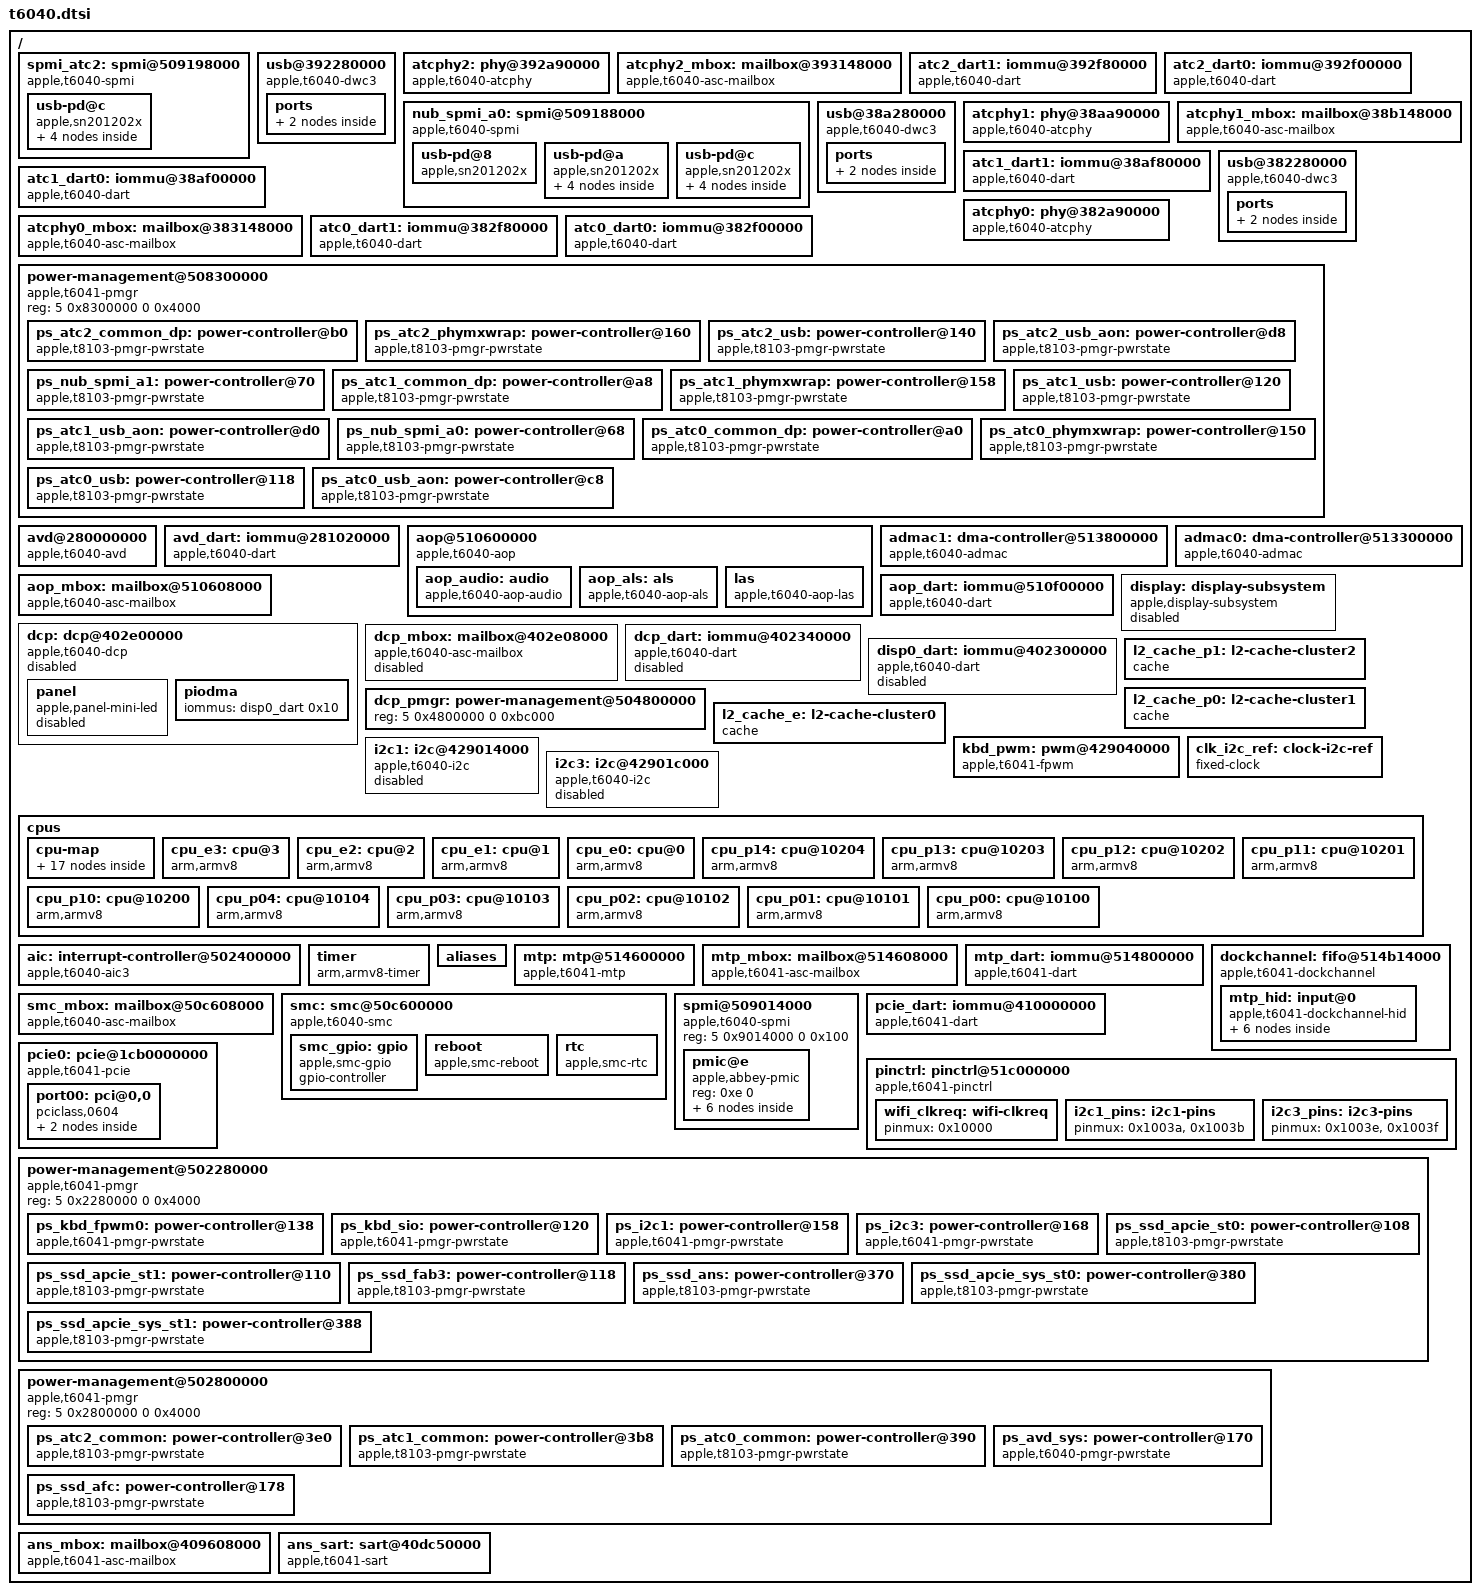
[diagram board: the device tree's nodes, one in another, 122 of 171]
// SPDX-License-Identifier: GPL-2.0+ OR MIT
/*
 * Apple T6040 (M4 Pro) SoC. Unit addresses are the ADT /arm-io addresses plus the 0x2_00000000 arm-io base.
 */

/ {
	#address-cells = <2>;
	#size-cells = <2>;

	/*
	 * The right-hand USB-C port (ATC2): the PD controller on its own SPMI bus, the ATC2 power states, both DARTs,
	 * the USB2 PHY and the dwc3 (USB2 host with hotplug). The two left ports below are the same stack.
	 */
	spmi_atc2: spmi@509198000 {
		compatible = "apple,t6040-spmi", "apple,spmi";
		reg = <5 0x9198000 0 0x100>;
		#address-cells = <2>;
		#size-cells = <0>;
		interrupt-controller;
		#interrupt-cells = <2>;
		interrupt-parent = <&aic>;
		interrupts = <0 0x364 4>;
		power-domains = <&ps_nub_spmi_a1>;

		usb-pd@c {
			compatible = "apple,sn201202x";
			reg = <0xc 0>;
			interrupts = <0xb 1 0xd 1 0x11 1 0x13 1>;
			interrupt-names = "irq", "select", "sleep", "wake";

			connector {
				compatible = "usb-c-connector";
				label = "USB-C Right";
				power-role = "dual";
				data-role = "dual";

				/*
				 * The HS endpoint names the dwc3 role switch: tipd looks it up at probe and defers
				 * until dwc3-apple has registered it.
				 */
				ports {
					#address-cells = <1>;
					#size-cells = <0>;

					port@0 {
						reg = <0>;
						typec2_connector_hs: endpoint {
							remote-endpoint = <&dwc3_2_hs>;
						};
					};
				};
			};
		};
	};

	usb@392280000 {
		compatible = "apple,t6040-dwc3", "apple,t8103-dwc3";
		reg = <3 0x92280000 0 0xcd00 3 0x9228cd00 0 0x3200>;
		reg-names = "dwc3-core", "dwc3-apple";
		interrupt-parent = <&aic>;
		interrupts = <0 0x693 4>;
		/*
		 * Role switch, not a fixed host: the PD controller resets the eUSB2 repeater on every CC connect, so the
		 * USB2 PHY and the core must start after the attach and stop on detach. The PHY has no device mode.
		 */
		dr_mode = "otg";
		usb-role-switch;
		role-switch-default-mode = "host";
		iommus = <&atc2_dart0 0 &atc2_dart1 1>;
		power-domains = <&ps_atc2_usb>;
		resets = <&atcphy2>;
		phys = <&atcphy2 3>;
		phy-names = "usb2-phy";

		ports {
			#address-cells = <1>;
			#size-cells = <0>;

			port@0 {
				reg = <0>;
				dwc3_2_hs: endpoint {
					remote-endpoint = <&typec2_connector_hs>;
				};
			};
		};
	};

	atcphy2: phy@392a90000 {
		compatible = "apple,t6040-atcphy";
		reg = <3 0x92a90000 0 0x4000 3 0x92800000 0 0x4000 3 0x92a84000 0 0x4000>;
		reg-names = "bank0", "bank1", "pipehandler";
		#phy-cells = <1>;
		#reset-cells = <0>;
		power-domains = <&ps_atc2_common_dp>;
		mboxes = <&atcphy2_mbox>;
		mbox-names = "phy-cpu";
	};

	/*
	 * The PHY coprocessor (ADT acio-phy-cpuN, "iop,mxwrap", RTKit) runs the SuperSpeed
	 * bring-up; its ASC v4 mailbox. ADT lists the IRQs as 1, 0, 3, 2 of the block,
	 * as for AOP: send-empty is the lowest.
	 */
	atcphy2_mbox: mailbox@393148000 {
		compatible = "apple,t6040-asc-mailbox", "apple,asc-mailbox-v4";
		reg = <3 0x93148000 0 0x4000>;
		interrupt-parent = <&aic>;
		interrupts = <0 0x3be 4 0 0x3bf 4 0 0x3c0 4 0 0x3c1 4>;
		interrupt-names = "send-empty", "send-not-empty", "recv-empty", "recv-not-empty";
		#mbox-cells = <0>;
		power-domains = <&ps_atc2_phymxwrap>;
	};

	atc2_dart1: iommu@392f80000 {
		compatible = "apple,t6040-dart", "apple,t8110-dart";
		reg = <3 0x92f80000 0 0x4000>;
		interrupt-parent = <&aic>;
		interrupts = <0 0x697 4>;
		power-domains = <&ps_atc2_usb>;
		#iommu-cells = <1>;
	};

	atc2_dart0: iommu@392f00000 {
		compatible = "apple,t6040-dart", "apple,t8110-dart";
		reg = <3 0x92f00000 0 0x4000>;
		interrupt-parent = <&aic>;
		interrupts = <0 0x697 4>;
		power-domains = <&ps_atc2_usb>;
		#iommu-cells = <1>;
	};

	/*
	 * The two left USB-C ports: left-front ATC1 (PD controller hpm1, SID 0xa) and left-back ATC0 (hpm0, SID 0xc),
	 * both PD controllers on nub-spmi-a0. Every ATCn address is ATC2's minus (2 - n) * 0x8000000 and every IRQ
	 * ATC2's minus (2 - n) * 0x20. The ADT lists only irq/sleep/wake; select is irq + 2, as on hpm2.
	 * nub-spmi-a0 also carries hpm5, the MagSafe 3 port (SID 8).
	 */
	nub_spmi_a0: spmi@509188000 {
		compatible = "apple,t6040-spmi", "apple,spmi";
		reg = <5 0x9188000 0 0x100>;
		#address-cells = <2>;
		#size-cells = <0>;
		interrupt-controller;
		#interrupt-cells = <2>;
		interrupt-parent = <&aic>;
		interrupts = <0 0x362 4>;
		power-domains = <&ps_nub_spmi_a0>;

		/*
		 * hpm5, the MagSafe 3 port's PD controller (ADT port-type 0x11, "Power In",
		 * no USB data path, no connector). tipd takes the port's capabilities from
		 * the controller and registers a Type-C port and a power supply for it, as
		 * for MagSafe on the M1 Pro/Max and the M2 Airs. Select is irq + 2.
		 */
		usb-pd@8 {
			compatible = "apple,sn201202x";
			reg = <0x8 0>;
			interrupts = <0x3f 1 0x41 1 0x45 1 0x47 1>;
			interrupt-names = "irq", "select", "sleep", "wake";
		};

		usb-pd@a {
			compatible = "apple,sn201202x";
			reg = <0xa 0>;
			interrupts = <0x25 1 0x27 1 0x2b 1 0x2d 1>;
			interrupt-names = "irq", "select", "sleep", "wake";

			connector {
				compatible = "usb-c-connector";
				label = "USB-C Left Front";
				power-role = "dual";
				data-role = "dual";

				ports {
					#address-cells = <1>;
					#size-cells = <0>;

					port@0 {
						reg = <0>;
						typec1_connector_hs: endpoint {
							remote-endpoint = <&dwc3_1_hs>;
						};
					};
				};
			};
		};

		/*
		 * hpm0, the left-back port's PD controller. DFU belongs to the boot ROM,
		 * before any OS runs, and macOS uses this port as a plain USB port too.
		 */
		usb-pd@c {
			compatible = "apple,sn201202x";
			reg = <0xc 0>;
			interrupts = <0xb 1 0xd 1 0x11 1 0x13 1>;
			interrupt-names = "irq", "select", "sleep", "wake";

			connector {
				compatible = "usb-c-connector";
				label = "USB-C Left Back";
				power-role = "dual";
				data-role = "dual";

				ports {
					#address-cells = <1>;
					#size-cells = <0>;

					port@0 {
						reg = <0>;
						typec0_connector_hs: endpoint {
							remote-endpoint = <&dwc3_0_hs>;
						};
					};
				};
			};
		};
	};

	usb@38a280000 {
		compatible = "apple,t6040-dwc3", "apple,t8103-dwc3";
		reg = <3 0x8a280000 0 0xcd00 3 0x8a28cd00 0 0x3200>;
		reg-names = "dwc3-core", "dwc3-apple";
		interrupt-parent = <&aic>;
		interrupts = <0 0x673 4>;
		dr_mode = "otg";
		usb-role-switch;
		role-switch-default-mode = "host";
		iommus = <&atc1_dart0 0 &atc1_dart1 1>;
		power-domains = <&ps_atc1_usb>;
		resets = <&atcphy1>;
		phys = <&atcphy1 3>;
		phy-names = "usb2-phy";

		ports {
			#address-cells = <1>;
			#size-cells = <0>;

			port@0 {
				reg = <0>;
				dwc3_1_hs: endpoint {
					remote-endpoint = <&typec1_connector_hs>;
				};
			};
		};
	};

	atcphy1: phy@38aa90000 {
		compatible = "apple,t6040-atcphy";
		reg = <3 0x8aa90000 0 0x4000 3 0x8a800000 0 0x4000 3 0x8aa84000 0 0x4000>;
		reg-names = "bank0", "bank1", "pipehandler";
		#phy-cells = <1>;
		#reset-cells = <0>;
		power-domains = <&ps_atc1_common_dp>;
		mboxes = <&atcphy1_mbox>;
		mbox-names = "phy-cpu";
	};

	atcphy1_mbox: mailbox@38b148000 {
		compatible = "apple,t6040-asc-mailbox", "apple,asc-mailbox-v4";
		reg = <3 0x8b148000 0 0x4000>;
		interrupt-parent = <&aic>;
		interrupts = <0 0x3b4 4 0 0x3b5 4 0 0x3b6 4 0 0x3b7 4>;
		interrupt-names = "send-empty", "send-not-empty", "recv-empty", "recv-not-empty";
		#mbox-cells = <0>;
		power-domains = <&ps_atc1_phymxwrap>;
	};

	atc1_dart1: iommu@38af80000 {
		compatible = "apple,t6040-dart", "apple,t8110-dart";
		reg = <3 0x8af80000 0 0x4000>;
		interrupt-parent = <&aic>;
		interrupts = <0 0x677 4>;
		power-domains = <&ps_atc1_usb>;
		#iommu-cells = <1>;
	};

	atc1_dart0: iommu@38af00000 {
		compatible = "apple,t6040-dart", "apple,t8110-dart";
		reg = <3 0x8af00000 0 0x4000>;
		interrupt-parent = <&aic>;
		interrupts = <0 0x677 4>;
		power-domains = <&ps_atc1_usb>;
		#iommu-cells = <1>;
	};

	usb@382280000 {
		compatible = "apple,t6040-dwc3", "apple,t8103-dwc3";
		reg = <3 0x82280000 0 0xcd00 3 0x8228cd00 0 0x3200>;
		reg-names = "dwc3-core", "dwc3-apple";
		interrupt-parent = <&aic>;
		interrupts = <0 0x653 4>;
		dr_mode = "otg";
		usb-role-switch;
		role-switch-default-mode = "host";
		iommus = <&atc0_dart0 0 &atc0_dart1 1>;
		power-domains = <&ps_atc0_usb>;
		resets = <&atcphy0>;
		phys = <&atcphy0 3>;
		phy-names = "usb2-phy";

		ports {
			#address-cells = <1>;
			#size-cells = <0>;

			port@0 {
				reg = <0>;
				dwc3_0_hs: endpoint {
					remote-endpoint = <&typec0_connector_hs>;
				};
			};
		};
	};

	atcphy0: phy@382a90000 {
		compatible = "apple,t6040-atcphy";
		reg = <3 0x82a90000 0 0x4000 3 0x82800000 0 0x4000 3 0x82a84000 0 0x4000>;
		reg-names = "bank0", "bank1", "pipehandler";
		#phy-cells = <1>;
		#reset-cells = <0>;
		power-domains = <&ps_atc0_common_dp>;
		mboxes = <&atcphy0_mbox>;
		mbox-names = "phy-cpu";
	};

	atcphy0_mbox: mailbox@383148000 {
		compatible = "apple,t6040-asc-mailbox", "apple,asc-mailbox-v4";
		reg = <3 0x83148000 0 0x4000>;
		interrupt-parent = <&aic>;
		interrupts = <0 0x3aa 4 0 0x3ab 4 0 0x3ac 4 0 0x3ad 4>;
		interrupt-names = "send-empty", "send-not-empty", "recv-empty", "recv-not-empty";
		#mbox-cells = <0>;
		power-domains = <&ps_atc0_phymxwrap>;
	};

	atc0_dart1: iommu@382f80000 {
		compatible = "apple,t6040-dart", "apple,t8110-dart";
		reg = <3 0x82f80000 0 0x4000>;
		interrupt-parent = <&aic>;
		interrupts = <0 0x657 4>;
		power-domains = <&ps_atc0_usb>;
		#iommu-cells = <1>;
	};

	atc0_dart0: iommu@382f00000 {
		compatible = "apple,t6040-dart", "apple,t8110-dart";
		reg = <3 0x82f00000 0 0x4000>;
		interrupt-parent = <&aic>;
		interrupts = <0 0x657 4>;
		power-domains = <&ps_atc0_usb>;
		#iommu-cells = <1>;
	};

	power-management@508300000 {
		compatible = "apple,t6041-pmgr", "apple,t8103-pmgr", "syscon", "simple-mfd";
		reg = <5 0x8300000 0 0x4000>;
		#address-cells = <1>;
		#size-cells = <1>;

		ps_atc2_common_dp: power-controller@b0 {
			compatible = "apple,t8103-pmgr-pwrstate";
			reg = <0xb0 4>;
			label = "atc2_common_dp";
			#power-domain-cells = <0>;
			#reset-cells = <0>;
			power-domains = <&ps_atc2_phymxwrap>;
		};

		ps_atc2_phymxwrap: power-controller@160 {
			compatible = "apple,t8103-pmgr-pwrstate";
			reg = <0x160 4>;
			label = "atc2_phymxwrap";
			#power-domain-cells = <0>;
			#reset-cells = <0>;
			power-domains = <&ps_atc2_common &ps_atc2_usb_aon>;
		};

		ps_atc2_usb: power-controller@140 {
			compatible = "apple,t8103-pmgr-pwrstate";
			reg = <0x140 4>;
			label = "atc2_usb";
			#power-domain-cells = <0>;
			#reset-cells = <0>;
			power-domains = <&ps_atc2_common &ps_atc2_usb_aon>;
		};

		ps_atc2_usb_aon: power-controller@d8 {
			compatible = "apple,t8103-pmgr-pwrstate";
			reg = <0xd8 4>;
			label = "atc2_usb_aon";
			#power-domain-cells = <0>;
			#reset-cells = <0>;
			apple,always-on;
		};

		ps_nub_spmi_a1: power-controller@70 {
			compatible = "apple,t8103-pmgr-pwrstate";
			reg = <0x70 4>;
			label = "nub_spmi_a1";
			#power-domain-cells = <0>;
			#reset-cells = <0>;
			apple,always-on;
		};

		/* The left-front port: the ATC2 shapes at the ATC1 offsets (ADT PS window 3). */
		ps_atc1_common_dp: power-controller@a8 {
			compatible = "apple,t8103-pmgr-pwrstate";
			reg = <0xa8 4>;
			label = "atc1_common_dp";
			#power-domain-cells = <0>;
			#reset-cells = <0>;
			power-domains = <&ps_atc1_phymxwrap>;
		};

		ps_atc1_phymxwrap: power-controller@158 {
			compatible = "apple,t8103-pmgr-pwrstate";
			reg = <0x158 4>;
			label = "atc1_phymxwrap";
			#power-domain-cells = <0>;
			#reset-cells = <0>;
			power-domains = <&ps_atc1_common &ps_atc1_usb_aon>;
		};

		ps_atc1_usb: power-controller@120 {
			compatible = "apple,t8103-pmgr-pwrstate";
			reg = <0x120 4>;
			label = "atc1_usb";
			#power-domain-cells = <0>;
			#reset-cells = <0>;
			power-domains = <&ps_atc1_common &ps_atc1_usb_aon>;
		};

		ps_atc1_usb_aon: power-controller@d0 {
			compatible = "apple,t8103-pmgr-pwrstate";
			reg = <0xd0 4>;
			label = "atc1_usb_aon";
			#power-domain-cells = <0>;
			#reset-cells = <0>;
			apple,always-on;
		};

		ps_nub_spmi_a0: power-controller@68 {
			compatible = "apple,t8103-pmgr-pwrstate";
			reg = <0x68 4>;
			label = "nub_spmi_a0";
			#power-domain-cells = <0>;
			#reset-cells = <0>;
			apple,always-on;
		};

		/* The left-back port: the ATC2 shapes at the ATC0 offsets (ADT PS window 3). */
		ps_atc0_common_dp: power-controller@a0 {
			compatible = "apple,t8103-pmgr-pwrstate";
			reg = <0xa0 4>;
			label = "atc0_common_dp";
			#power-domain-cells = <0>;
			#reset-cells = <0>;
			power-domains = <&ps_atc0_phymxwrap>;
		};

		ps_atc0_phymxwrap: power-controller@150 {
			compatible = "apple,t8103-pmgr-pwrstate";
			reg = <0x150 4>;
			label = "atc0_phymxwrap";
			#power-domain-cells = <0>;
			#reset-cells = <0>;
			power-domains = <&ps_atc0_common &ps_atc0_usb_aon>;
		};

		ps_atc0_usb: power-controller@118 {
			compatible = "apple,t8103-pmgr-pwrstate";
			reg = <0x118 4>;
			label = "atc0_usb";
			#power-domain-cells = <0>;
			#reset-cells = <0>;
			power-domains = <&ps_atc0_common &ps_atc0_usb_aon>;
		};

		ps_atc0_usb_aon: power-controller@c8 {
			compatible = "apple,t8103-pmgr-pwrstate";
			reg = <0xc8 4>;
			label = "atc0_usb_aon";
			#power-domain-cells = <0>;
			#reset-cells = <0>;
			apple,always-on;
		};
	};

	/*
	 * The video decoder: the MCU firmware programs the t8122/t8132 register family, so apple-avd binds through
	 * its t8132 entry; the DART and the AVD_SYS power state bind through the generic drivers.
	 */
	avd@280000000 {
		compatible = "apple,t6040-avd", "apple,t8132-avd";
		reg = <2 0x81080000 0 0x14000 2 0x810a8000 0 0x4000 2 0x81100000 0 0x10000>;
		reg-names = "code", "mbox", "ctrl";
		interrupt-parent = <&aic>;
		interrupts = <0 0x5a2 4 0 0x5a3 4>;
		power-domains = <&ps_avd_sys>;
		resets = <&ps_avd_sys>;
		iommus = <&avd_dart 0>;
	};

	avd_dart: iommu@281020000 {
		compatible = "apple,t6040-dart", "apple,t8110-dart";
		reg = <2 0x81020000 0 0xc000>;
		#iommu-cells = <1>;
		interrupt-parent = <&aic>;
		interrupts = <0 0x5a9 4>;
		power-domains = <&ps_avd_sys>;
	};

	aop@510600000 {
		compatible = "apple,t6040-aop";
		reg = <5 0x10c10000 0 0x2e0000 5 0x10600000 0 0x88000 5 0x10050000 0 0x4000 5 0x8328000 0 0x24>;
		reg-names = "firmware", "asc", "asc-aux", "config";
		mboxes = <&aop_mbox>;
		mbox-names = "mbox";
		iommus = <&aop_dart 0>;
		#address-cells = <2>;
		#size-cells = <2>;

		/*
		 * "dma" is the microphones' leap ADMAC channel. "spkr" and "sense" are the speaker
		 * stream's base-ns ADMAC channels 0 and 1 (ADT audio-speaker dma-channels).
		 */
		aop_audio: audio {
			compatible = "apple,t6040-aop-audio", "apple,t6030-aop-audio";
			apple,chassis-name = "J616";
			apple,machine-kind = "MacBook Pro";
			dmas = <&admac0 1>, <&admac1 0>, <&admac1 1>;
			dma-names = "dma", "spkr", "sense";
			#sound-dai-cells = <1>;
		};

		aop_als: als {
			compatible = "apple,t6040-aop-als", "apple,aop-als";
		};

		las {
			compatible = "apple,t6040-aop-las", "apple,aop-las";
		};
	};

	admac1: dma-controller@513800000 {
		compatible = "apple,t6040-admac", "apple,t8132-admac";
		reg = <5 0x13800000 0 0x34000>;
		#dma-cells = <1>;
		dma-channels = <0xd>;
		interrupt-parent = <&aic>;
		interrupts = <0 0x2f2 4>;
		iommus = <&aop_dart 8>;
	};

	admac0: dma-controller@513300000 {
		compatible = "apple,t6040-admac", "apple,t8132-admac";
		reg = <5 0x13300000 0 0x34000>;
		#dma-cells = <1>;
		dma-channels = <0x12>;
		interrupt-parent = <&aic>;
		interrupts = <0 0x2f5 4>;
		iommus = <&aop_dart 0xa>;
	};

	aop_mbox: mailbox@510608000 {
		compatible = "apple,t6040-asc-mailbox", "apple,asc-mailbox-v4";
		reg = <5 0x10608000 0 0x4000>;
		interrupt-parent = <&aic>;
		interrupts = <0 0x2c6 4 0 0x2c7 4 0 0x2c8 4 0 0x2c9 4>;
		interrupt-names = "send-empty", "send-not-empty", "recv-empty", "recv-not-empty";
		#mbox-cells = <0>;
	};

	aop_dart: iommu@510f00000 {
		compatible = "apple,t6040-dart", "apple,t8110-dart";
		reg = <5 0x10f00000 0 0xc000>, <5 0x10f10000 0 0x4000>;
		#iommu-cells = <1>;
		interrupt-parent = <&aic>;
		interrupts = <0 0x2de 4>;
		/* the J616s ADT's filter data for this DART: <start end r0 r4 r20> */
		apple,dapf-entries = /bits/ 64 <
			0x5081e4020 0x5081e4043 0x31 0x0 0x1
			0x5081e4880 0x5081e4c50 0x31 0x0 0x1
			0x508240004 0x508240373 0x31 0x0 0x1
			0x508304000 0x50830416b 0x31 0x0 0x1
			0x508320280 0x50832048b 0x31 0x0 0x1
			0x508370000 0x5083709a3 0x31 0x0 0x1
			0x508900014 0x508900017 0x31 0x0 0x1
			0x50c618110 0x50c61881f 0x31 0x0 0x1
			0x50c634000 0x50c634003 0x31 0x0 0x1
			0x50de00000 0x50defffff 0x31 0x0 0x1
			0x508018000 0x50801bfff 0x31 0x0 0x1
			0x50801c000 0x50801ffff 0x31 0x0 0x1
		>;
	};

	display: display-subsystem {
		compatible = "apple,display-subsystem";
		iommus = <&disp0_dart 0>;
		dma-noncoherent;
		status = "disabled";
	};

	dcp: dcp@402e00000 {
		compatible = "apple,t6040-dcp", "apple,dcp";
		reg = <4 0x2e00000 0 0x4000 4 0 0 0x4000000 4 0x2240000 0 0x10000 4 0x23a8000 0 0x4000 4 0x2800000 0 0x800000>;
		reg-names = "coproc", "disp-0", "disp-1", "disp-2", "disp-3";
		mboxes = <&dcp_mbox>;
		mbox-names = "mbox";
		iommus = <&dcp_dart 0x17>;
		apple,bw-scratch = <&dcp_pmgr 0 4 0x20000>;
		apple,iomfb-surfaces = <1 1 0 0>;
		apple,iomfb-surface-order = <0 1>;
		apple,iomfb-primary-surface = <0>;
		apple,iomfb-max-layers = <2>;
		apple,firmware-version = <0x1a 6 2>;
		apple,firmware-compat = <0x1a 6 2>;
		#address-cells = <2>;
		#size-cells = <2>;
		status = "disabled";

		panel {
			compatible = "apple,panel-mini-led", "apple,panel";
			width-mm = <0x159>;
			height-mm = <0xdf>;
			status = "disabled";
		};

		piodma: piodma {
			iommus = <&disp0_dart 0x10>;
		};
	};

	dcp_mbox: mailbox@402e08000 {
		compatible = "apple,t6040-asc-mailbox", "apple,asc-mailbox-v4";
		reg = <4 0x2e08000 0 0x4000>;
		interrupt-parent = <&aic>;
		interrupts = <0 0x477 4 0 0x478 4 0 0x479 4 0 0x47a 4>;
		interrupt-names = "send-empty", "send-not-empty", "recv-empty", "recv-not-empty";
		#mbox-cells = <0>;
		status = "disabled";
	};

	dcp_dart: iommu@402340000 {
		compatible = "apple,t6040-dart", "apple,t8110-dart";
		reg = <4 0x2340000 0 0x20000>;
		#iommu-cells = <1>;
		interrupt-parent = <&aic>;
		interrupts = <0 0x442 4>;
		status = "disabled";
	};

	disp0_dart: iommu@402300000 {
		compatible = "apple,t6040-dart", "apple,t8110-dart";
		reg = <4 0x2300000 0 0xc000>;
		#iommu-cells = <1>;
		interrupt-parent = <&aic>;
		interrupts = <0 0x442 4>;
		status = "disabled";
	};

	dcp_pmgr: power-management@504800000 {
		reg = <5 0x4800000 0 0xbc000>;
		reg-names = "dcp-fw-pmgr";
		#apple,bw-scratch-cells = <3>;
	};

	l2_cache_p1: l2-cache-cluster2 {
		compatible = "cache";
		cache-level = <2>;
		cache-size = <0x1000000>;
		cache-unified;
	};

	l2_cache_p0: l2-cache-cluster1 {
		compatible = "cache";
		cache-level = <2>;
		cache-size = <0x1000000>;
		cache-unified;
	};

	l2_cache_e: l2-cache-cluster0 {
		compatible = "cache";
		cache-level = <2>;
		cache-size = <0x400000>;
		cache-unified;
	};

	kbd_pwm: pwm@429040000 {
		compatible = "apple,t6041-fpwm", "apple,s5l-fpwm";
		reg = <4 0x29040000 0 0x4000>;
		clocks = <&clk_kbd_pwm>;
		power-domains = <&ps_kbd_fpwm0>;
		#pwm-cells = <2>;
		status = "okay";
	};

	/*
	 * The speaker-amp buses: i2c1 carries the left amps, i2c3 the right ones (t6040-j616s.dts). iBoot leaves both
	 * gates on and the pins muxed to I2C; the 24 MHz reference is the controllers' input clock (100 kHz = divider 15).
	 */
	clk_i2c_ref: clock-i2c-ref {
		compatible = "fixed-clock";
		#clock-cells = <0>;
		clock-frequency = <24000000>;
		clock-output-names = "i2c_ref";
	};

	i2c1: i2c@429014000 {
		compatible = "apple,t6040-i2c", "apple,t8103-i2c";
		reg = <4 0x29014000 0 0x4000>;
		clocks = <&clk_i2c_ref>;
		interrupt-parent = <&aic>;
		interrupts = <0 0x628 4>;
		pinctrl-0 = <&i2c1_pins>;
		pinctrl-names = "default";
		power-domains = <&ps_i2c1>;
		#address-cells = <1>;
		#size-cells = <0>;
		status = "disabled";
	};

	i2c3: i2c@42901c000 {
		compatible = "apple,t6040-i2c", "apple,t8103-i2c";
		reg = <4 0x2901c000 0 0x4000>;
		clocks = <&clk_i2c_ref>;
		interrupt-parent = <&aic>;
		interrupts = <0 0x62a 4>;
		pinctrl-0 = <&i2c3_pins>;
		pinctrl-names = "default";
		power-domains = <&ps_i2c3>;
		#address-cells = <1>;
		#size-cells = <0>;
		status = "disabled";
	};

	cpus {
		#size-cells = <0>;
		#address-cells = <2>;

		/*
		 * Clusters = MPIDR Aff1 = the L2 groups. capacity-dmips-mhz from pinned single-core throughput at p-state 1
		 * (E 1018 MHz, P 1257 MHz; Kb2uka's benchmark method): E/P 0.652 per MHz, so E 668 and P 1024. The kernel
		 * reads capacity-dmips-mhz only through cpu-map.
		 */
		cpu-map {
			cluster0 {
				core0 {
					cpu = <&cpu_e0>;
				};
				core1 {
					cpu = <&cpu_e1>;
				};
				core2 {
					cpu = <&cpu_e2>;
				};
				core3 {
					cpu = <&cpu_e3>;
				};
			};
			cluster1 {
				core0 {
					cpu = <&cpu_p00>;
				};
				core1 {
					cpu = <&cpu_p01>;
				};
				core2 {
					cpu = <&cpu_p02>;
				};
				core3 {
					cpu = <&cpu_p03>;
				};
				core4 {
					cpu = <&cpu_p04>;
				};
			};
			cluster2 {
				core0 {
					cpu = <&cpu_p10>;
				};
				core1 {
					cpu = <&cpu_p11>;
				};
				core2 {
					cpu = <&cpu_p12>;
				};
				core3 {
					cpu = <&cpu_p13>;
				};
				core4 {
					cpu = <&cpu_p14>;
				};
			};
		};

		cpu_e3: cpu@3 {
			compatible = "arm,armv8";
			reg = <0 3>;
			device_type = "cpu";
			enable-method = "spin-table";
			next-level-cache = <&l2_cache_e>;
			capacity-dmips-mhz = <668>;
			status = "okay";
		};

		cpu_e2: cpu@2 {
			compatible = "arm,armv8";
			reg = <0 2>;
			device_type = "cpu";
			enable-method = "spin-table";
			next-level-cache = <&l2_cache_e>;
			capacity-dmips-mhz = <668>;
			status = "okay";
		};

		cpu_e1: cpu@1 {
			compatible = "arm,armv8";
			reg = <0 1>;
			device_type = "cpu";
			enable-method = "spin-table";
			next-level-cache = <&l2_cache_e>;
			capacity-dmips-mhz = <668>;
			status = "okay";
		};

		cpu_e0: cpu@0 {
			compatible = "arm,armv8";
			reg = <0 0>;
			device_type = "cpu";
			enable-method = "spin-table";
			next-level-cache = <&l2_cache_e>;
			capacity-dmips-mhz = <668>;
			status = "okay";
		};

		cpu_p14: cpu@10204 {
			compatible = "arm,armv8";
			reg = <0 0x10204>;
			device_type = "cpu";
			enable-method = "spin-table";
			next-level-cache = <&l2_cache_p1>;
			capacity-dmips-mhz = <1024>;
			status = "okay";
		};

		cpu_p13: cpu@10203 {
			compatible = "arm,armv8";
			reg = <0 0x10203>;
			device_type = "cpu";
			enable-method = "spin-table";
			next-level-cache = <&l2_cache_p1>;
			capacity-dmips-mhz = <1024>;
			status = "okay";
		};

		cpu_p12: cpu@10202 {
			compatible = "arm,armv8";
			reg = <0 0x10202>;
			device_type = "cpu";
			enable-method = "spin-table";
			next-level-cache = <&l2_cache_p1>;
			capacity-dmips-mhz = <1024>;
			status = "okay";
		};

		cpu_p11: cpu@10201 {
			compatible = "arm,armv8";
			reg = <0 0x10201>;
			device_type = "cpu";
			enable-method = "spin-table";
			next-level-cache = <&l2_cache_p1>;
			capacity-dmips-mhz = <1024>;
			status = "okay";
		};

		cpu_p10: cpu@10200 {
			compatible = "arm,armv8";
			reg = <0 0x10200>;
			device_type = "cpu";
			enable-method = "spin-table";
			next-level-cache = <&l2_cache_p1>;
			capacity-dmips-mhz = <1024>;
			status = "okay";
		};

		cpu_p04: cpu@10104 {
			compatible = "arm,armv8";
			reg = <0 0x10104>;
			device_type = "cpu";
			enable-method = "spin-table";
			next-level-cache = <&l2_cache_p0>;
			capacity-dmips-mhz = <1024>;
			status = "okay";
		};

		cpu_p03: cpu@10103 {
			compatible = "arm,armv8";
			reg = <0 0x10103>;
			device_type = "cpu";
			enable-method = "spin-table";
			next-level-cache = <&l2_cache_p0>;
			capacity-dmips-mhz = <1024>;
			status = "okay";
		};

		cpu_p02: cpu@10102 {
			compatible = "arm,armv8";
			reg = <0 0x10102>;
			device_type = "cpu";
			enable-method = "spin-table";
			next-level-cache = <&l2_cache_p0>;
			capacity-dmips-mhz = <1024>;
			status = "okay";
		};

		cpu_p01: cpu@10101 {
			compatible = "arm,armv8";
			reg = <0 0x10101>;
			device_type = "cpu";
			enable-method = "spin-table";
			next-level-cache = <&l2_cache_p0>;
			capacity-dmips-mhz = <1024>;
			status = "okay";
		};

		cpu_p00: cpu@10100 {
			compatible = "arm,armv8";
			reg = <0 0x10100>;
			device_type = "cpu";
			next-level-cache = <&l2_cache_p0>;
			capacity-dmips-mhz = <1024>;
			status = "okay";
		};
	};

	aic: interrupt-controller@502400000 {
		compatible = "apple,t6040-aic3", "apple,t8122-aic3";
		reg = <5 0x2400000 0 0x184000 5 0x2440000 0 4>;
		reg-names = "core", "event";
		#address-cells = <0>;
		interrupt-controller;
		#interrupt-cells = <3>;
	};

	timer {
		compatible = "arm,armv8-timer";
		interrupts = <1 2 4 1 3 4 1 0 4 1 1 4>;
		interrupt-names = "phys", "virt", "hyp-phys", "hyp-virt";
		interrupt-parent = <&aic>;
	};

	aliases {
		keyboard = "/fifo@514b14000/input@0/keyboard";
		wifi0 = "/pcie@1cb0000000/pci@0,0/wifi@0,0";
		bluetooth0 = "/pcie@1cb0000000/pci@0,0/bluetooth@0,1";
		dcp = "/dcp@402e00000";
		disp0 = "/display-subsystem";
		disp0_piodma = "/dcp@402e00000/piodma";
	};

	mtp: mtp@514600000 {
		compatible = "apple,t6041-mtp", "apple,t6041-rtk-helper-asc4", "apple,mtp", "apple,rtk-helper-asc4";
		reg = <5 0x14600000 0 0x4000>;
		reg-names = "asc";
		#helper-cells = <0>;
		iommus = <&mtp_dart 0>;
		mboxes = <&mtp_mbox>;
	};

	mtp_mbox: mailbox@514608000 {
		compatible = "apple,t6041-asc-mailbox", "apple,asc-mailbox-v4";
		reg = <5 0x14608000 0 0x4000>;
		#mbox-cells = <0>;
		interrupt-names = "send-empty", "send-not-empty", "recv-empty", "recv-not-empty";
		interrupts = <0 0x318 4 0 0x319 4 0 0x31a 4 0 0x31b 4>;
		interrupt-parent = <&aic>;
	};

	mtp_dart: iommu@514800000 {
		compatible = "apple,t6041-dart", "apple,t8110-dart";
		reg = <5 0x14800000 0 0xc000>;
		apple,remap-streams = <1 0>, <2 0>, <3 0>;
		#iommu-cells = <1>;
		interrupts = <0 0x307 4>;
		interrupt-parent = <&aic>;
	};

	dockchannel: fifo@514b14000 {
		compatible = "apple,t6041-dockchannel", "apple,dockchannel";
		reg = <5 0x14b14000 0 0x1000>;
		reg-names = "irq";
		ranges = <0 5 0x14b28000 0x10000>;
		#interrupt-cells = <2>;
		interrupt-controller;
		#size-cells = <1>;
		#address-cells = <1>;
		nonposted-mmio;
		interrupts = <0 0x308 4>;
		interrupt-parent = <&aic>;

		mtp_hid: input@0 {
			compatible = "apple,t6041-dockchannel-hid", "apple,dockchannel-hid";
			reg = <0 0x1000 0x4000 0x1000 0x8000 0x1000 0xc000 0x1000>;
			reg-names = "rmt-config", "rmt-data", "config", "data";
			apple,helper-cpu = <&mtp>;
			apple,fifo-size = <0x800>;
			interrupt-names = "tx", "rx";
			interrupts = <2 4 3 4>;
			interrupt-parent = <&dockchannel>;
			iommus = <&mtp_dart 0>;

			multi-touch {
				firmware-name = "apple/tpmtfw-j616s.bin";
			};

			keyboard {
				apple,keyboard-layout-id = <2>;
				hid-country-code = <0>;
			};

			stm {
			};

			actuator {
			};

			tp-accel {
			};

			mtp {
			};
		};
	};

	smc_mbox: mailbox@50c608000 {
		compatible = "apple,t6040-asc-mailbox", "apple,asc-mailbox-v4";
		reg = <5 0xc608000 0 0x4000>;
		#mbox-cells = <0>;
		interrupt-names = "send-empty", "send-not-empty", "recv-empty", "recv-not-empty";
		interrupts = <0 0x3e4 4 0 0x3e5 4 0 0x3e6 4 0 0x3e7 4>;
		interrupt-parent = <&aic>;
	};

	smc: smc@50c600000 {
		compatible = "apple,t6040-smc", "apple,t8103-smc", "apple,smc";
		reg = <5 0xc600000 0 0x4000 5 0xde70000 0 0x100000>;
		reg-names = "smc", "sram";
		mboxes = <&smc_mbox>;

		smc_gpio: gpio {
			compatible = "apple,smc-gpio";
			#gpio-cells = <2>;
			gpio-controller;
		};

		reboot {
			compatible = "apple,smc-reboot";
			nvmem-cell-names = "shutdown_flag", "boot_stage", "boot_error_count", "panic_count";
			nvmem-cells = <&shutdown_flag_f80f_3 &boot_stage_f801 &boot_error_count_f802_0 &panic_count_f802_4>;
		};

		rtc {
			compatible = "apple,smc-rtc";
			nvmem-cells = <&rtc_offset>;
			nvmem-cell-names = "rtc_offset";
		};
	};

	spmi@509014000 {
		compatible = "apple,t6040-spmi", "apple,spmi";
		reg = <5 0x9014000 0 0x100>;
		#size-cells = <0>;
		#address-cells = <2>;

		pmic@e {
			compatible = "apple,abbey-pmic", "apple,spmi-nvmem";
			reg = <0xe 0>;

			nvmem-layout {
				compatible = "fixed-layout";
				#size-cells = <1>;
				#address-cells = <1>;

				rtc_offset: rtc-offset@2100 {
					reg = <0x2100 6>;
				};

				boot_stage_f801: boot-stage@f801 {
					reg = <0xf801 1>;
				};

				boot_error_count_f802_0: boot-error-count@f802,0 {
					reg = <0xf802 1>;
					bits = <0 4>;
				};

				panic_count_f802_4: panic-count@f802,4 {
					reg = <0xf802 1>;
					bits = <4 4>;
				};

				shutdown_flag_f80f_3: shutdown-flag@f80f,3 {
					reg = <0xf80f 1>;
					bits = <3 1>;
				};
			};
		};
	};

	pcie_dart: iommu@410000000 {
		compatible = "apple,t6041-dart", "apple,t8110-dart";
		reg = <4 0x10000000 0 0x4000>;
		interrupts = <0 0x6bc 4>;
		interrupt-parent = <&aic>;
		#iommu-cells = <1>;
	};

	pinctrl: pinctrl@51c000000 {
		compatible = "apple,t6041-pinctrl", "apple,t8103-pinctrl";
		reg = <5 0x1c000000 0 0x4000>;
		interrupts = <0 0x1de 4 0 0x1df 4 0 0x1e0 4 0 0x1e1 4 0 0x1e2 4 0 0x1e3 4 0 0x1e4 4>;
		interrupt-parent = <&aic>;
		#interrupt-cells = <2>;
		interrupt-controller;
		apple,npins = <0xc8>;
		gpio-ranges = <&pinctrl 0 0 200>;
		#gpio-cells = <2>;
		gpio-controller;

		wifi_clkreq: wifi-clkreq {
			pinmux = <0x10000>;
		};

		/* (function << 16) | pin: I2C is function 1 (ADT gpio-iic_scl/sda) */
		i2c1_pins: i2c1-pins {
			pinmux = <0x1003a>, <0x1003b>;
		};

		i2c3_pins: i2c3-pins {
			pinmux = <0x1003e>, <0x1003f>;
		};
	};

	pcie0: pcie@1cb0000000 {
		compatible = "apple,t6041-pcie", "apple,t6020-pcie";
		reg = <0x1c 0xb0000000 0 0x1000000 4 0x14000000 0 0x4000 4 0x10028000 0 0x4000 4 0x17020000 0 0x4000>;
		reg-names = "config", "rc", "port0", "phy0";
		ranges = <0x43000000 0xb 0xc0000000 0xb 0xc0000000 0 0x20000000 0x2000000 0 0x80000000 0xb 0x80000000 0 0x40000000>;
		pinctrl-names = "default";
		pinctrl-0 = <&wifi_clkreq>;
		#size-cells = <2>;
		#address-cells = <3>;
		bus-range = <0 1>;
		iommu-map-mask = <0xffff>;
		iommu-map = <0x100 &pcie_dart 1 2>;
		msi-ranges = <1 0 0x817 1 0x20>;
		msi-parent = <&pcie0>;
		msi-controller;
		interrupts = <0 0x6bb 4>;
		interrupt-parent = <&aic>;
		device_type = "pci";

		port00: pci@0,0 {
			compatible = "pciclass,0604";
			reg = <0 0 0 0 0>;
			ranges;
			interrupt-map = <0 0 0 1 &port00 0 0 0 0 0 0 0 2 &port00 0 0 0 1 0 0 0 3 &port00 0 0 0 2 0 0 0 4 &port00 0 0 0 3>;
			interrupt-map-mask = <0 0 0 7>;
			#interrupt-cells = <1>;
			interrupt-controller;
			#size-cells = <2>;
			#address-cells = <3>;
			pwren-gpios = <&smc_gpio 0x13 0>;
			reset-gpios = <&pinctrl 4 1>;
			device_type = "pci";

			bluetooth@0,1 {
				compatible = "pci14e4,5f72";
				reg = <0x100 0 0 0 0>;
				brcm,board-type = "apple,hostomel";
				status = "okay";
			};

			wifi@0,0 {
				compatible = "brcm,bcm4329-fmac";
				reg = <0 0 0 0 0>;
				brcm,ccode-map-trivial;
				brcm,board-type = "apple,hostomel";
			};
		};
	};

	power-management@502280000 {
		compatible = "apple,t6041-pmgr", "apple,t8103-pmgr", "syscon", "simple-mfd";
		reg = <5 0x2280000 0 0x4000>;
		#size-cells = <1>;
		#address-cells = <1>;

		ps_kbd_fpwm0: power-controller@138 {
			compatible = "apple,t6041-pmgr-pwrstate", "apple,t8103-pmgr-pwrstate";
			reg = <0x138 4>;
			label = "kbd_fpwm0";
			#power-domain-cells = <0>;
			#reset-cells = <0>;
			power-domains = <&ps_kbd_sio>;
		};

		ps_kbd_sio: power-controller@120 {
			compatible = "apple,t6041-pmgr-pwrstate", "apple,t8103-pmgr-pwrstate";
			reg = <0x120 4>;
			label = "kbd_sio";
			#power-domain-cells = <0>;
			#reset-cells = <0>;
			power-domains = <&ps_ssd_fab3>;
			apple,always-on;
		};

		/* ADT pmgr devices I2C1 (0xad) and I2C3 (0xaf), both children of SIO (0xa6) */
		ps_i2c1: power-controller@158 {
			compatible = "apple,t6041-pmgr-pwrstate", "apple,t8103-pmgr-pwrstate";
			reg = <0x158 4>;
			label = "i2c1";
			#power-domain-cells = <0>;
			#reset-cells = <0>;
			power-domains = <&ps_kbd_sio>;
		};

		ps_i2c3: power-controller@168 {
			compatible = "apple,t6041-pmgr-pwrstate", "apple,t8103-pmgr-pwrstate";
			reg = <0x168 4>;
			label = "i2c3";
			#power-domain-cells = <0>;
			#reset-cells = <0>;
			power-domains = <&ps_kbd_sio>;
		};

		ps_ssd_apcie_st0: power-controller@108 {
			compatible = "apple,t8103-pmgr-pwrstate";
			reg = <0x108 4>;
			apple,always-on;
			#reset-cells = <0>;
			#power-domain-cells = <0>;
			label = "ssd_apcie_st0";
		};

		ps_ssd_apcie_st1: power-controller@110 {
			compatible = "apple,t8103-pmgr-pwrstate";
			reg = <0x110 4>;
			apple,always-on;
			#reset-cells = <0>;
			#power-domain-cells = <0>;
			label = "ssd_apcie_st1";
		};

		ps_ssd_fab3: power-controller@118 {
			compatible = "apple,t8103-pmgr-pwrstate";
			reg = <0x118 4>;
			power-domains = <&ps_ssd_afc>;
			apple,always-on;
			#reset-cells = <0>;
			#power-domain-cells = <0>;
			label = "ssd_fab3";
		};

		ps_ssd_ans: power-controller@370 {
			compatible = "apple,t8103-pmgr-pwrstate";
			reg = <0x370 4>;
			power-domains = <&ps_ssd_fab3>;
			apple,always-on;
			#reset-cells = <0>;
			#power-domain-cells = <0>;
			label = "ssd_ans";
		};

		ps_ssd_apcie_sys_st0: power-controller@380 {
			compatible = "apple,t8103-pmgr-pwrstate";
			reg = <0x380 4>;
			power-domains = <&ps_ssd_ans &ps_ssd_apcie_st0>;
			apple,always-on;
			#reset-cells = <0>;
			#power-domain-cells = <0>;
			label = "ssd_apcie_sys_st0";
		};

		ps_ssd_apcie_sys_st1: power-controller@388 {
			compatible = "apple,t8103-pmgr-pwrstate";
			reg = <0x388 4>;
			power-domains = <&ps_ssd_ans &ps_ssd_apcie_st1>;
			apple,always-on;
			#reset-cells = <0>;
			#power-domain-cells = <0>;
			label = "ssd_apcie_sys_st1";
		};
	};

	power-management@502800000 {
		compatible = "apple,t6041-pmgr", "apple,t8103-pmgr", "syscon", "simple-mfd";
		reg = <5 0x2800000 0 0x4000>;
		#size-cells = <1>;
		#address-cells = <1>;

		/*
		 * Always-on: the firmware leaves atc2_usb on while its parent atc2_common is power-gated, and genpd
		 * refuses an active child under an off parent (-EINVAL). Its fabric parents are on at boot.
		 */
		ps_atc2_common: power-controller@3e0 {
			compatible = "apple,t8103-pmgr-pwrstate";
			reg = <0x3e0 4>;
			label = "atc2_common";
			#power-domain-cells = <0>;
			#reset-cells = <0>;
			apple,always-on;
		};

		/*
		 * The left-front port's ATC1_COMMON (ADT 0x6b, PS 0x5_028003b8): always-on for the
		 * same reason as atc2_common above. Whether the firmware also leaves ATC1_USB on
		 * under it is unknown, and an inconsistent pair stops genpd with -EINVAL.
		 */
		ps_atc1_common: power-controller@3b8 {
			compatible = "apple,t8103-pmgr-pwrstate";
			reg = <0x3b8 4>;
			label = "atc1_common";
			#power-domain-cells = <0>;
			#reset-cells = <0>;
			apple,always-on;
		};

		/* The left-back port's ATC0_COMMON (ADT 0x66, PS 0x5_02800390): as atc1_common. */
		ps_atc0_common: power-controller@390 {
			compatible = "apple,t8103-pmgr-pwrstate";
			reg = <0x390 4>;
			label = "atc0_common";
			#power-domain-cells = <0>;
			#reset-cells = <0>;
			apple,always-on;
		};

		ps_avd_sys: power-controller@170 {
			compatible = "apple,t6040-pmgr-pwrstate", "apple,t8103-pmgr-pwrstate";
			reg = <0x170 4>;
			label = "avd_sys";
			#power-domain-cells = <0>;
			#reset-cells = <0>;
		};

		ps_ssd_afc: power-controller@178 {
			compatible = "apple,t8103-pmgr-pwrstate";
			reg = <0x178 4>;
			apple,always-on;
			#reset-cells = <0>;
			#power-domain-cells = <0>;
			label = "ssd_afc";
		};
	};

	ans_mbox: mailbox@409608000 {
		compatible = "apple,t6041-asc-mailbox", "apple,asc-mailbox-v4";
		reg = <4 0x9608000 0 0x4000>;
		power-domains = <&ps_ssd_ans>;
		interrupt-names = "send-empty", "send-not-empty", "recv-empty", "recv-not-empty";
		interrupts = <0 0x5fa 4 0 0x5fb 4 0 0x5fc 4 0 0x5fd 4>;
		interrupt-parent = <&aic>;
		#mbox-cells = <0>;
	};

	ans_sart: sart@40dc50000 {
		compatible = "apple,t6041-sart", "apple,t6000-sart";
		reg = <4 0xdc50000 0 0xc000>;
		power-domains = <&ps_ssd_ans>;
	};
};
